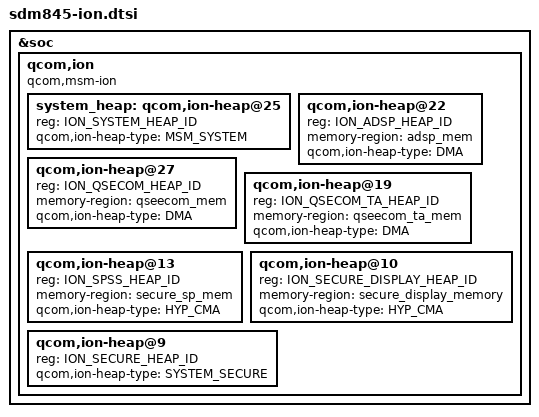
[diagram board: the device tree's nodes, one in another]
// SPDX-License-Identifier: GPL-2.0-only
/*
 * Copyright (c) 2016-2017, The Linux Foundation. All rights reserved.
 * Copyright (c) 2021, 2025, Pavel Dubrova <pashadubrova@gmail.com>
 */

#include <dt-bindings/arm/msm/msm_ion_ids.h>

&soc {
	qcom,ion {
		compatible = "qcom,msm-ion";
		#address-cells = <1>;
		#size-cells = <0>;

		system_heap: qcom,ion-heap@25 {
			reg = <ION_SYSTEM_HEAP_ID>;
			qcom,ion-heap-type = "MSM_SYSTEM";
		};

		qcom,ion-heap@22 { /* ADSP HEAP */
			reg = <ION_ADSP_HEAP_ID>;
			memory-region = <&adsp_mem>;
			qcom,ion-heap-type = "DMA";
		};

		qcom,ion-heap@27 { /* QSEECOM HEAP */
			reg = <ION_QSECOM_HEAP_ID>;
			memory-region = <&qseecom_mem>;
			qcom,ion-heap-type = "DMA";
		};

		qcom,ion-heap@19 { /* QSEECOM TA HEAP */
			reg = <ION_QSECOM_TA_HEAP_ID>;
			memory-region = <&qseecom_ta_mem>;
			qcom,ion-heap-type = "DMA";
		};

		qcom,ion-heap@13 { /* SECURE SPSS HEAP */
			reg = <ION_SPSS_HEAP_ID>;
			memory-region = <&secure_sp_mem>;
			qcom,ion-heap-type = "HYP_CMA";
		};

		qcom,ion-heap@10 { /* SECURE DISPLAY HEAP */
			reg = <ION_SECURE_DISPLAY_HEAP_ID>;
			memory-region = <&secure_display_memory>;
			qcom,ion-heap-type = "HYP_CMA";
		};

		qcom,ion-heap@9 {
			reg = <ION_SECURE_HEAP_ID>;
			qcom,ion-heap-type = "SYSTEM_SECURE";
		};
	};
};
